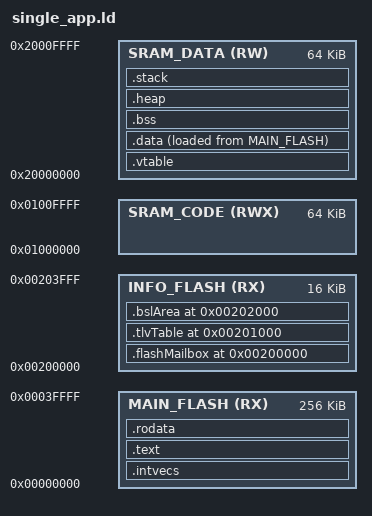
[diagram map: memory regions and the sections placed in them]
MEMORY
{
    MAIN_FLASH (RX) : ORIGIN = 0x00000000, LENGTH = 0x00040000
    INFO_FLASH (RX) : ORIGIN = 0x00200000, LENGTH = 0x00004000
    SRAM_CODE  (RWX): ORIGIN = 0x01000000, LENGTH = 0x00010000
    SRAM_DATA  (RW) : ORIGIN = 0x20000000, LENGTH = 0x00010000
}

REGION_ALIAS("REGION_TEXT", MAIN_FLASH);
REGION_ALIAS("REGION_INFO", INFO_FLASH);
REGION_ALIAS("REGION_BSS", SRAM_DATA);
REGION_ALIAS("REGION_DATA", SRAM_DATA);
REGION_ALIAS("REGION_STACK", SRAM_DATA);
REGION_ALIAS("REGION_HEAP", SRAM_DATA);

SECTIONS {

    /* section for the interrupt vector area                                 */
    PROVIDE (_intvecs_base_address =
        DEFINED(_intvecs_base_address) ? _intvecs_base_address : 0x0);

    .intvecs (_intvecs_base_address) : AT (_intvecs_base_address) {
        KEEP (*(.intvecs))
    } > REGION_TEXT

    /* The following three sections show the usage of the INFO flash memory  */
    /* INFO flash memory is intended to be used for the following            */
    /* device specific purposes:                                             */
    /* Flash mailbox for device security operations                          */
    PROVIDE (_mailbox_base_address = 0x200000);

    .flashMailbox (_mailbox_base_address) : AT (_mailbox_base_address) {
        KEEP (*(.flashMailbox))
    } > REGION_INFO

    /* TLV table for device identification and characterization              */
    PROVIDE (_tlv_base_address = 0x00201000);

    .tlvTable (_tlv_base_address) (NOLOAD) : AT (_tlv_base_address) {
        KEEP (*(.tlvTable))
    } > REGION_INFO

    /* BSL area for device bootstrap loader                                  */
    PROVIDE (_bsl_base_address = 0x00202000);

    .bslArea (_bsl_base_address) : AT (_bsl_base_address) {
        KEEP (*(.bslArea))
    } > REGION_INFO

    PROVIDE (_vtable_base_address =
        DEFINED(_vtable_base_address) ? _vtable_base_address : 0x20000000);

    .vtable (_vtable_base_address) : AT (_vtable_base_address) {
        KEEP (*(.vtable))
    } > REGION_DATA

    .text : {
        CREATE_OBJECT_SYMBOLS
        KEEP (*(.text))
        *(.text.*)
        . = ALIGN(0x4);
        KEEP (*(.ctors))
        . = ALIGN(0x4);
        KEEP (*(.dtors))
        . = ALIGN(0x4);
        __init_array_start = .;
        KEEP (*(.init_array*))
        __init_array_end = .;
        KEEP (*(.init))
        KEEP (*(.fini*))
    } > REGION_TEXT AT> REGION_TEXT

    .rodata : {
        *(.rodata)
        *(.rodata.*)
    } > REGION_TEXT AT> REGION_TEXT

    .ARM.exidx : {
        __exidx_start = .;
        *(.ARM.exidx* .gnu.linkonce.armexidx.*)
        __exidx_end = .;
    } > REGION_ARM_EXIDX AT> REGION_ARM_EXIDX

    .ARM.extab : {
        KEEP (*(.ARM.extab* .gnu.linkonce.armextab.*))
    } > REGION_ARM_EXTAB AT> REGION_ARM_EXTAB

    __etext = .;

    .data : {
        __data_load__ = LOADADDR (.data);
        __data_start__ = .;
        KEEP (*(.data))
        KEEP (*(.data*))
        . = ALIGN (4);
        __data_end__ = .;
    } > REGION_DATA AT> REGION_TEXT

    .bss : {
        __bss_start__ = .;
        *(.shbss)
        KEEP (*(.bss))
        *(.bss.*)
        *(COMMON)
        . = ALIGN (4);
        __bss_end__ = .;
    } > REGION_BSS AT> REGION_BSS

    .heap : {
        __heap_start__ = .;
        end = __heap_start__;
        _end = end;
        __end = end;
        KEEP (*(.heap))
        __heap_end__ = .;
        __HeapLimit = __heap_end__;
    } > REGION_HEAP AT> REGION_HEAP

    .stack (NOLOAD) : ALIGN(0x8) {
        _stack = .;
        KEEP(*(.stack))
    } > REGION_STACK AT> REGION_STACK
	
	__StackTop = ORIGIN(REGION_STACK) + LENGTH(REGION_STACK);
    PROVIDE(__stack = __StackTop);
}
